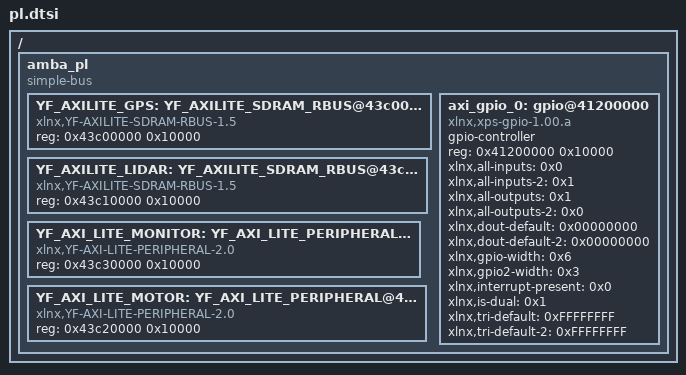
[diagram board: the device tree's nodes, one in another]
/*
 * CAUTION: This file is automatically generated by Xilinx.
 * Version: HSI 2015.4
 * Today is: Fri Mar 27 15:55:12 2020
*/


/ {
	amba_pl: amba_pl {
		#address-cells = <1>;
		#size-cells = <1>;
		compatible = "simple-bus";
		ranges ;
		YF_AXILITE_GPS: YF_AXILITE_SDRAM_RBUS@43c00000 {
			compatible = "xlnx,YF-AXILITE-SDRAM-RBUS-1.5";
			reg = <0x43c00000 0x10000>;
		};
		YF_AXILITE_LIDAR: YF_AXILITE_SDRAM_RBUS@43c10000 {
			compatible = "xlnx,YF-AXILITE-SDRAM-RBUS-1.5";
			reg = <0x43c10000 0x10000>;
		};
		YF_AXI_LITE_MONITOR: YF_AXI_LITE_PERIPHERAL@43c30000 {
			compatible = "xlnx,YF-AXI-LITE-PERIPHERAL-2.0";
			reg = <0x43c30000 0x10000>;
		};
		YF_AXI_LITE_MOTOR: YF_AXI_LITE_PERIPHERAL@43c20000 {
			compatible = "xlnx,YF-AXI-LITE-PERIPHERAL-2.0";
			reg = <0x43c20000 0x10000>;
		};
		axi_gpio_0: gpio@41200000 {
			#gpio-cells = <2>;
			compatible = "xlnx,xps-gpio-1.00.a";
			gpio-controller ;
			reg = <0x41200000 0x10000>;
			xlnx,all-inputs = <0x0>;
			xlnx,all-inputs-2 = <0x1>;
			xlnx,all-outputs = <0x1>;
			xlnx,all-outputs-2 = <0x0>;
			xlnx,dout-default = <0x00000000>;
			xlnx,dout-default-2 = <0x00000000>;
			xlnx,gpio-width = <0x6>;
			xlnx,gpio2-width = <0x3>;
			xlnx,interrupt-present = <0x0>;
			xlnx,is-dual = <0x1>;
			xlnx,tri-default = <0xFFFFFFFF>;
			xlnx,tri-default-2 = <0xFFFFFFFF>;
		};
	};
};
